VERSION ""

NS_ :

BS_:

BU_: XXX X

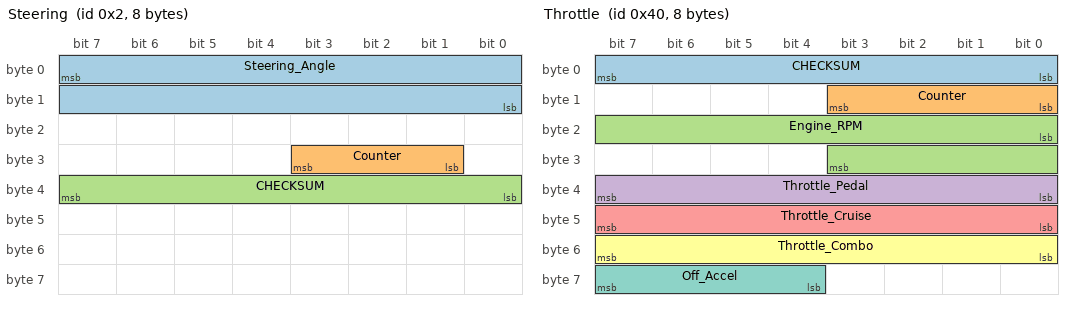
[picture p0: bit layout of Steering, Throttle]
BO_ 2 Steering: 8 XXX
 SG_ Steering_Angle : 7|16@0- (0.1,0) [0|65535] "" XXX
 SG_ Counter : 25|3@1+ (1,0) [0|7] "" XXX
 SG_ CHECKSUM : 32|8@1+ (1,0) [0|255] "" XXX

BO_ 64 Throttle: 8 XXX
 SG_ CHECKSUM : 0|8@1+ (1,0) [0|255] "" XXX
 SG_ Counter : 8|4@1+ (1,0) [0|255] "" XXX
 SG_ Engine_RPM : 16|12@1+ (1,0) [0|255] "" XXX
 SG_ Throttle_Pedal : 32|8@1+ (1,0) [0|255] "" XXX
 SG_ Throttle_Cruise : 40|8@1+ (1,0) [0|255] "" XXX
 SG_ Throttle_Combo : 48|8@1+ (1,0) [0|255] "" XXX
 SG_ Off_Accel : 60|4@1+ (1,0) [0|7] "" XXX

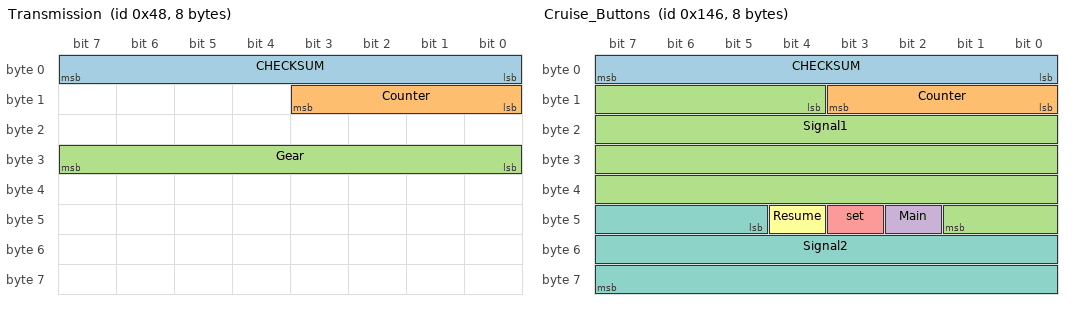
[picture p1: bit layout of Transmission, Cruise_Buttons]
BO_ 72 Transmission: 8 XXX
 SG_ CHECKSUM : 0|8@1+ (1,0) [0|255] "" XXX
 SG_ Counter : 8|4@1+ (1,0) [0|15] "" XXX
 SG_ Gear : 24|8@1+ (1,0) [0|255] "" XXX

BO_ 326 Cruise_Buttons: 8 XXX
 SG_ CHECKSUM : 0|8@1+ (1,0) [0|255] "" XXX
 SG_ Counter : 8|4@1+ (1,0) [0|15] "" XXX
 SG_ Signal1 : 12|30@1+ (1,0) [0|1073741823] "" XXX
 SG_ Main : 42|1@1+ (1,0) [0|1] "" XXX
 SG_ set : 43|1@1+ (1,0) [0|1] "" XXX
 SG_ Resume : 44|1@1+ (1,0) [0|1] "" XXX
 SG_ Signal2 : 45|19@1+ (1,0) [0|524287] "" XXX

BO_ 315 G_Sensor: 8 XXX
 SG_ Lateral : 48|8@1- (-0.1,0) [0|255] "m/s2" XXX
 SG_ Longitudinal : 56|8@1- (-0.1,0) [0|255] "m/s2" XXX

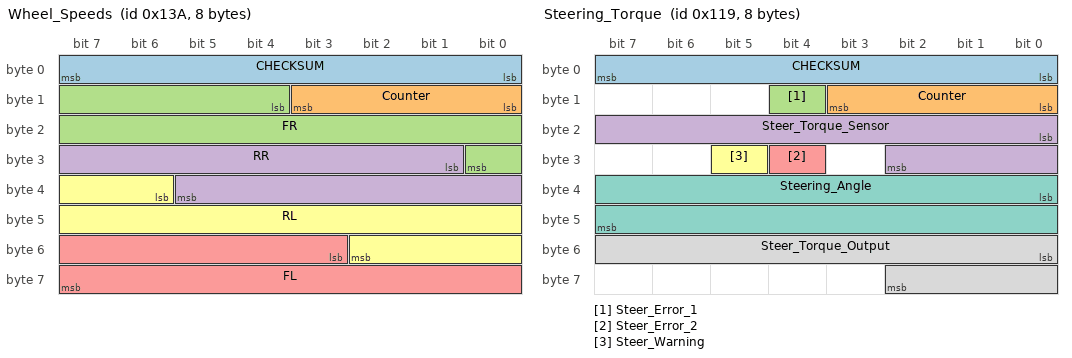
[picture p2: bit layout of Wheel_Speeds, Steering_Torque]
BO_ 314 Wheel_Speeds: 8 XXX
 SG_ CHECKSUM : 0|8@1+ (1,0) [0|255] "" XXX
 SG_ Counter : 8|4@1+ (1,0) [0|15] "" XXX
 SG_ FR : 12|13@1+ (0.057,0) [0|255] "kph" XXX
 SG_ RR : 25|13@1+ (0.057,0) [0|255] "kph" XXX
 SG_ FL : 51|13@1+ (0.057,0) [0|255] "kph" XXX
 SG_ RL : 38|13@1+ (0.057,0) [0|255] "kph" XXX

BO_ 281 Steering_Torque: 8 XXX
 SG_ CHECKSUM : 0|8@1+ (1,0) [0|3] "" XXX
 SG_ Counter : 8|4@1+ (1,0) [0|15] "" XXX
 SG_ Steer_Error_1 : 12|1@0+ (1,0) [0|1] "" XXX
 SG_ Steer_Torque_Sensor : 16|11@1- (-1,0) [0|3] "" XXX
 SG_ Steer_Error_2 : 28|1@1+ (1,0) [0|1] "" XXX
 SG_ Steer_Warning : 29|1@1+ (1,0) [0|1] "" XXX
 SG_ Steering_Angle : 32|16@1- (-0.0217,0) [0|255] "" X
 SG_ Steer_Torque_Output : 48|11@1- (-1,0) [0|31] "" XXX

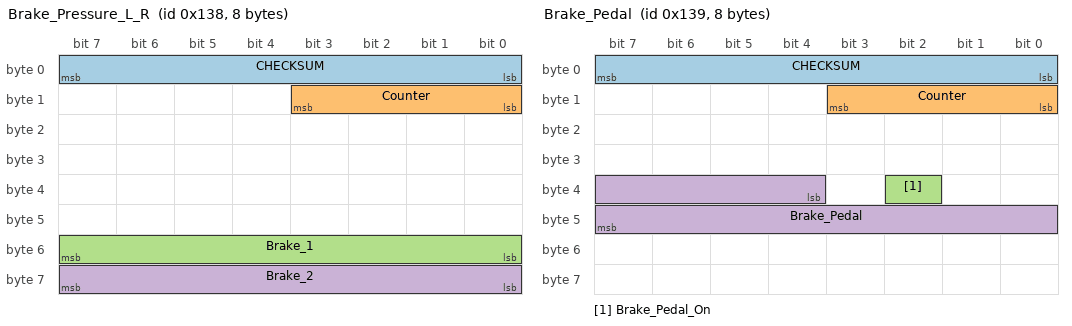
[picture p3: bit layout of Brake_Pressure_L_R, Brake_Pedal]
BO_ 312 Brake_Pressure_L_R: 8 XXX
 SG_ CHECKSUM : 0|8@1+ (1,0) [0|31] "" XXX
 SG_ Counter : 8|4@1+ (1,0) [0|3] "" XXX
 SG_ Brake_1 : 48|8@1+ (1,0) [0|255] "" XXX
 SG_ Brake_2 : 56|8@1+ (1,0) [0|255] "" XXX

BO_ 313 Brake_Pedal: 8 XXX
 SG_ CHECKSUM : 0|8@1+ (1,0) [0|255] "" XXX
 SG_ Counter : 8|4@1+ (1,0) [0|15] "" XXX
 SG_ Brake_Pedal_On : 34|1@1+ (1,0) [0|7] "" XXX
 SG_ Brake_Pedal : 36|12@1+ (1,0) [0|65535] "" XXX

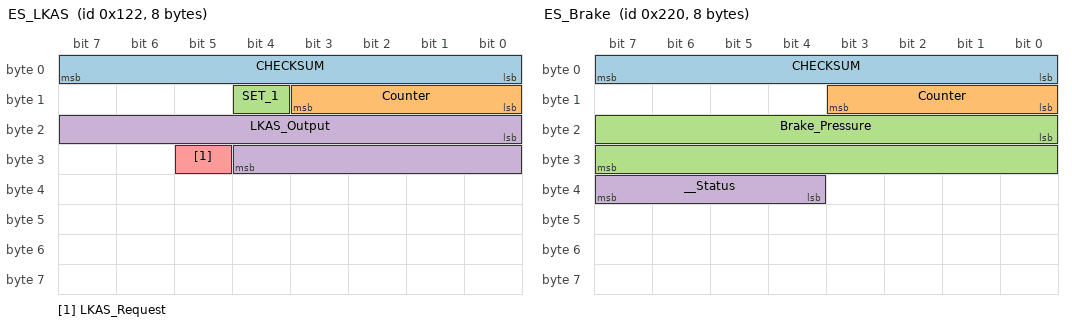
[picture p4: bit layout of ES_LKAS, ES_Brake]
BO_ 290 ES_LKAS: 8 XXX
 SG_ CHECKSUM : 0|8@1+ (1,0) [0|255] "" XXX
 SG_ Counter : 8|4@1+ (1,0) [0|15] "" XXX
 SG_ SET_1 : 12|1@0+ (1,0) [0|3] "" XXX
 SG_ LKAS_Output : 16|13@1- (-1,0) [0|3] "" XXX
 SG_ LKAS_Request : 29|1@0+ (1,0) [0|3] "" XXX

BO_ 544 ES_Brake: 8 XXX
 SG_ CHECKSUM : 0|8@1+ (1,0) [0|255] "" XXX
 SG_ Counter : 8|4@1+ (1,0) [0|15] "" XXX
 SG_ Brake_Pressure : 16|16@1+ (1,0) [0|255] "" XXX
 SG_ __Status : 36|4@1+ (1,0) [0|63] "" XXX

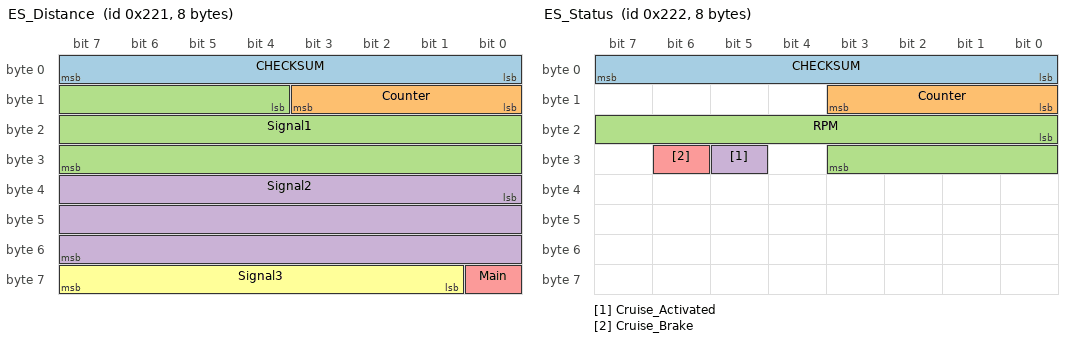
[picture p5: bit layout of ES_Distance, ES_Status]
BO_ 545 ES_Distance: 8 XXX
 SG_ CHECKSUM : 0|8@1+ (1,0) [0|255] "" XXX
 SG_ Counter : 8|4@1+ (1,0) [0|15] "" XXX
 SG_ Signal1 : 12|20@1+ (1,0) [0|15] "" XXX
 SG_ Signal2 : 32|24@1+ (1,0) [0|15] "" XXX
 SG_ Main : 56|1@1+ (1,0) [0|1] "" XXX
 SG_ Signal3 : 57|7@1+ (1,0) [0|1] "" XXX

BO_ 546 ES_Status: 8 XXX
 SG_ CHECKSUM : 0|8@1+ (1,0) [0|255] "" XXX
 SG_ Counter : 8|4@1+ (1,0) [0|15] "" XXX
 SG_ RPM : 16|12@1+ (1,0) [0|255] "" XXX
 SG_ Cruise_Activated : 29|1@0+ (1,0) [0|3] "" XXX
 SG_ Cruise_Brake : 30|1@1+ (1,0) [0|3] "" XXX

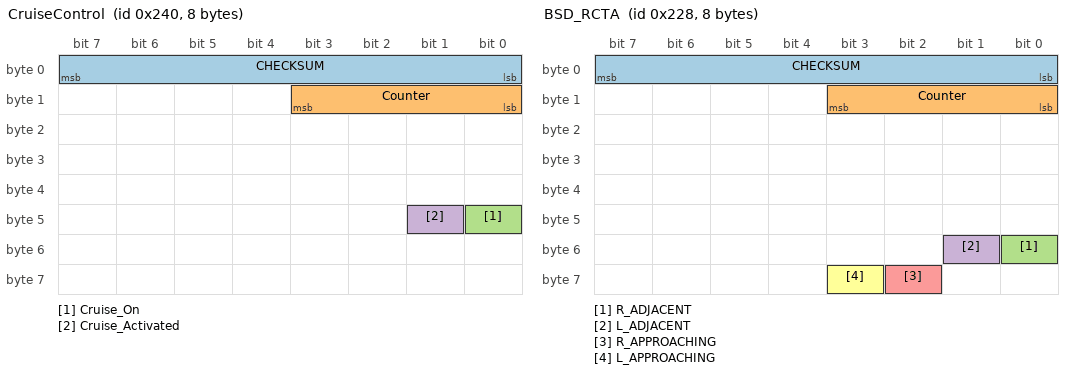
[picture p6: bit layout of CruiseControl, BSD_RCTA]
BO_ 576 CruiseControl: 8 XXX
 SG_ CHECKSUM : 0|8@1+ (1,0) [0|255] "" XXX
 SG_ Counter : 8|4@1+ (1,0) [0|15] "" XXX
 SG_ Cruise_On : 40|1@1+ (1,0) [0|3] "" XXX
 SG_ Cruise_Activated : 41|1@1+ (1,0) [0|3] "" XXX

BO_ 552 BSD_RCTA: 8 XXX
 SG_ CHECKSUM : 0|8@1+ (1,0) [0|255] "" XXX
 SG_ Counter : 8|4@1+ (1,0) [0|15] "" XXX
 SG_ R_ADJACENT : 48|1@1+ (1,0) [0|1] "" XXX
 SG_ L_ADJACENT : 49|1@1+ (1,0) [0|1] "" XXX
 SG_ R_APPROACHING : 58|1@1+ (1,0) [0|1] "" XXX
 SG_ L_APPROACHING : 59|1@1+ (1,0) [0|1] "" XXX

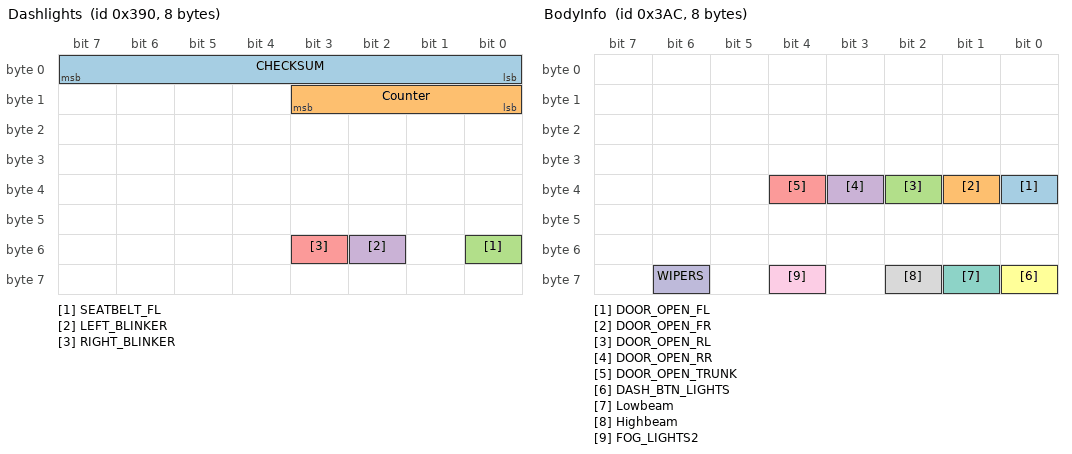
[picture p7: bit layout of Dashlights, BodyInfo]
BO_ 912 Dashlights: 8 XXX
 SG_ CHECKSUM : 0|8@1+ (1,0) [0|255] "" XXX
 SG_ Counter : 8|4@1+ (1,0) [0|15] "" XXX
 SG_ SEATBELT_FL : 48|1@1+ (1,0) [0|1] "" XXX
 SG_ LEFT_BLINKER : 50|1@1+ (1,0) [0|3] "" XXX
 SG_ RIGHT_BLINKER : 51|1@1+ (1,0) [0|1] "" XXX

BO_ 940 BodyInfo: 8 XXX
 SG_ DOOR_OPEN_FL : 32|1@1+ (1,0) [0|255] "" XXX
 SG_ DOOR_OPEN_FR : 33|1@1+ (1,0) [0|3] "" XXX
 SG_ DOOR_OPEN_RL : 34|1@1+ (1,0) [0|1] "" XXX
 SG_ DOOR_OPEN_RR : 35|1@1+ (1,0) [0|1] "" XXX
 SG_ DOOR_OPEN_TRUNK : 36|1@0+ (1,0) [0|1] "" XXX
 SG_ DASH_BTN_LIGHTS : 56|1@0+ (1,0) [0|1] "" XXX
 SG_ Lowbeam : 57|1@1+ (1,0) [0|3] "" XXX
 SG_ Highbeam : 58|1@1+ (1,0) [0|1] "" XXX
 SG_ FOG_LIGHTS2 : 60|1@1+ (1,0) [0|1] "" XXX
 SG_ WIPERS : 62|1@0+ (1,0) [0|1] "" XXX

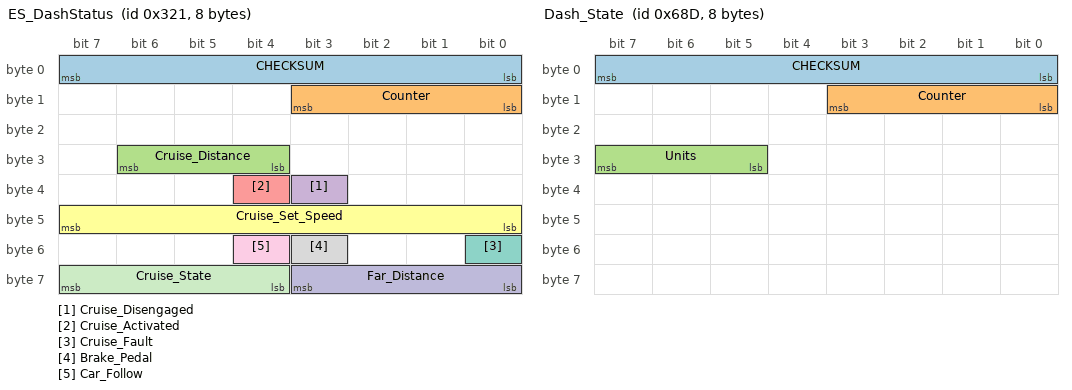
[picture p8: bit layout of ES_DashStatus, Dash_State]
BO_ 801 ES_DashStatus: 8 XXX
 SG_ CHECKSUM : 0|8@1+ (1,0) [0|255] "" XXX
 SG_ Counter : 8|4@1+ (1,0) [0|7] "" XXX
 SG_ Cruise_Distance : 28|3@1+ (1,0) [0|3] "" XXX
 SG_ Cruise_Disengaged : 35|1@1+ (1,0) [0|3] "" XXX
 SG_ Cruise_Activated : 36|1@1+ (1,0) [0|3] "" XXX
 SG_ Cruise_Set_Speed : 40|8@1+ (1,0) [0|255] "" XXX
 SG_ Cruise_Fault : 48|1@1+ (1,0) [0|1] "" XXX
 SG_ Brake_Pedal : 51|1@1+ (1,0) [0|3] "" XXX
 SG_ Car_Follow : 52|1@1+ (1,0) [0|3] "" XXX
 SG_ Far_Distance : 56|4@1+ (1,0) [0|15] "" XXX
 SG_ Cruise_State : 60|4@1+ (1,0) [0|15] "" XXX

BO_ 802 ES_LKAS_State: 8 XXX
 SG_ CHECKSUM : 0|8@1+ (1,0) [0|255] "" XXX
 SG_ Counter : 8|4@1+ (1,0) [0|15] "" XXX
 SG_ Keep_Hands_On_Wheel : 12|1@1+ (1,0) [0|1] "" XXX
 SG_ Empty_Box : 13|1@1+ (1,0) [0|1] "" XXX
 SG_ Signal1 : 14|3@1+ (1,0) [0|7] "" XXX
 SG_ LKAS_ACTIVE : 17|1@1+ (1,0) [0|3] "" XXX
 SG_ Signal2 : 18|5@1+ (1,0) [0|7] "" XXX
 SG_ Backward_Speed_Limit_Menu : 23|1@1+ (1,0) [0|1] "" XXX
 SG_ LKAS_ENABLE_3 : 24|1@1+ (1,0) [0|1] "" XXX
 SG_ Signal3 : 25|1@1+ (1,0) [0|1] "" XXX
 SG_ LKAS_ENABLE_2 : 26|1@1+ (1,0) [0|1] "" XXX
 SG_ Signal4 : 27|1@1+ (1,0) [0|1] "" XXX
 SG_ LKAS_Left_Line_Visible : 28|1@1+ (1,0) [0|1] "" XXX
 SG_ Signal6 : 29|1@1+ (1,0) [0|1] "" XXX
 SG_ LKAS_Right_Line_Visible : 30|1@1+ (1,0) [0|1] "" XXX
 SG_ Signal7 : 31|1@1+ (1,0) [0|1] "" XXX
 SG_ FCW_Cont_Beep : 32|1@1+ (1,0) [0|1] "" XXX
 SG_ FCW_Repeated_Beep : 33|1@1+ (1,0) [0|1] "" XXX
 SG_ Throttle_Management_Activated : 34|1@1+ (1,0) [0|1] "" XXX
 SG_ Traffic_light_Ahead : 35|1@1+ (1,0) [0|1] "" XXX
 SG_ Right_Depart : 36|1@1+ (1,0) [0|3] "" XXX
 SG_ Signal5 : 37|27@1+ (1,0) [0|1] "" XXX

BO_ 1677 Dash_State: 8 XXX
 SG_ CHECKSUM : 0|8@1+ (1,0) [0|255] "" XXX
 SG_ Counter : 8|4@1+ (1,0) [0|15] "" XXX
 SG_ Units : 29|3@1+ (1,0) [0|7] "" XXX

BO_ 256 OP_ACTIVE: 8 XXX
 SG_ ACTIVE : 0|4@1+ (1,0) [0|1] "" XXX

CM_ SG_ 940 FOG_LIGHTS2 "yellow fog light in the dash";
CM_ SG_ 940 Highbeam "01 = low beam, 11 = high beam";
CM_ SG_ 801 Cruise_State "0 = Normal, 3 = Hold";
CM_ SG_ 802 Traffic_light_Ahead "Crosstrek 2018 = car in front has moved";
CM_ SG_ 940 FOG_LIGHTS2 "yellow fog light in the dash";
CM_ SG_ 940 Highbeam "01 = low beam, 11 = high beam";
CM_ SG_ 1677 Units "1 = imperial, 6 = metric";
VAL_ 72 Gear 2 "N" 3 "R" 4 "P" 121 "D" 137 "1" 145 "2" 153 "3" 161 "4" 169 "5" 177 "6";
